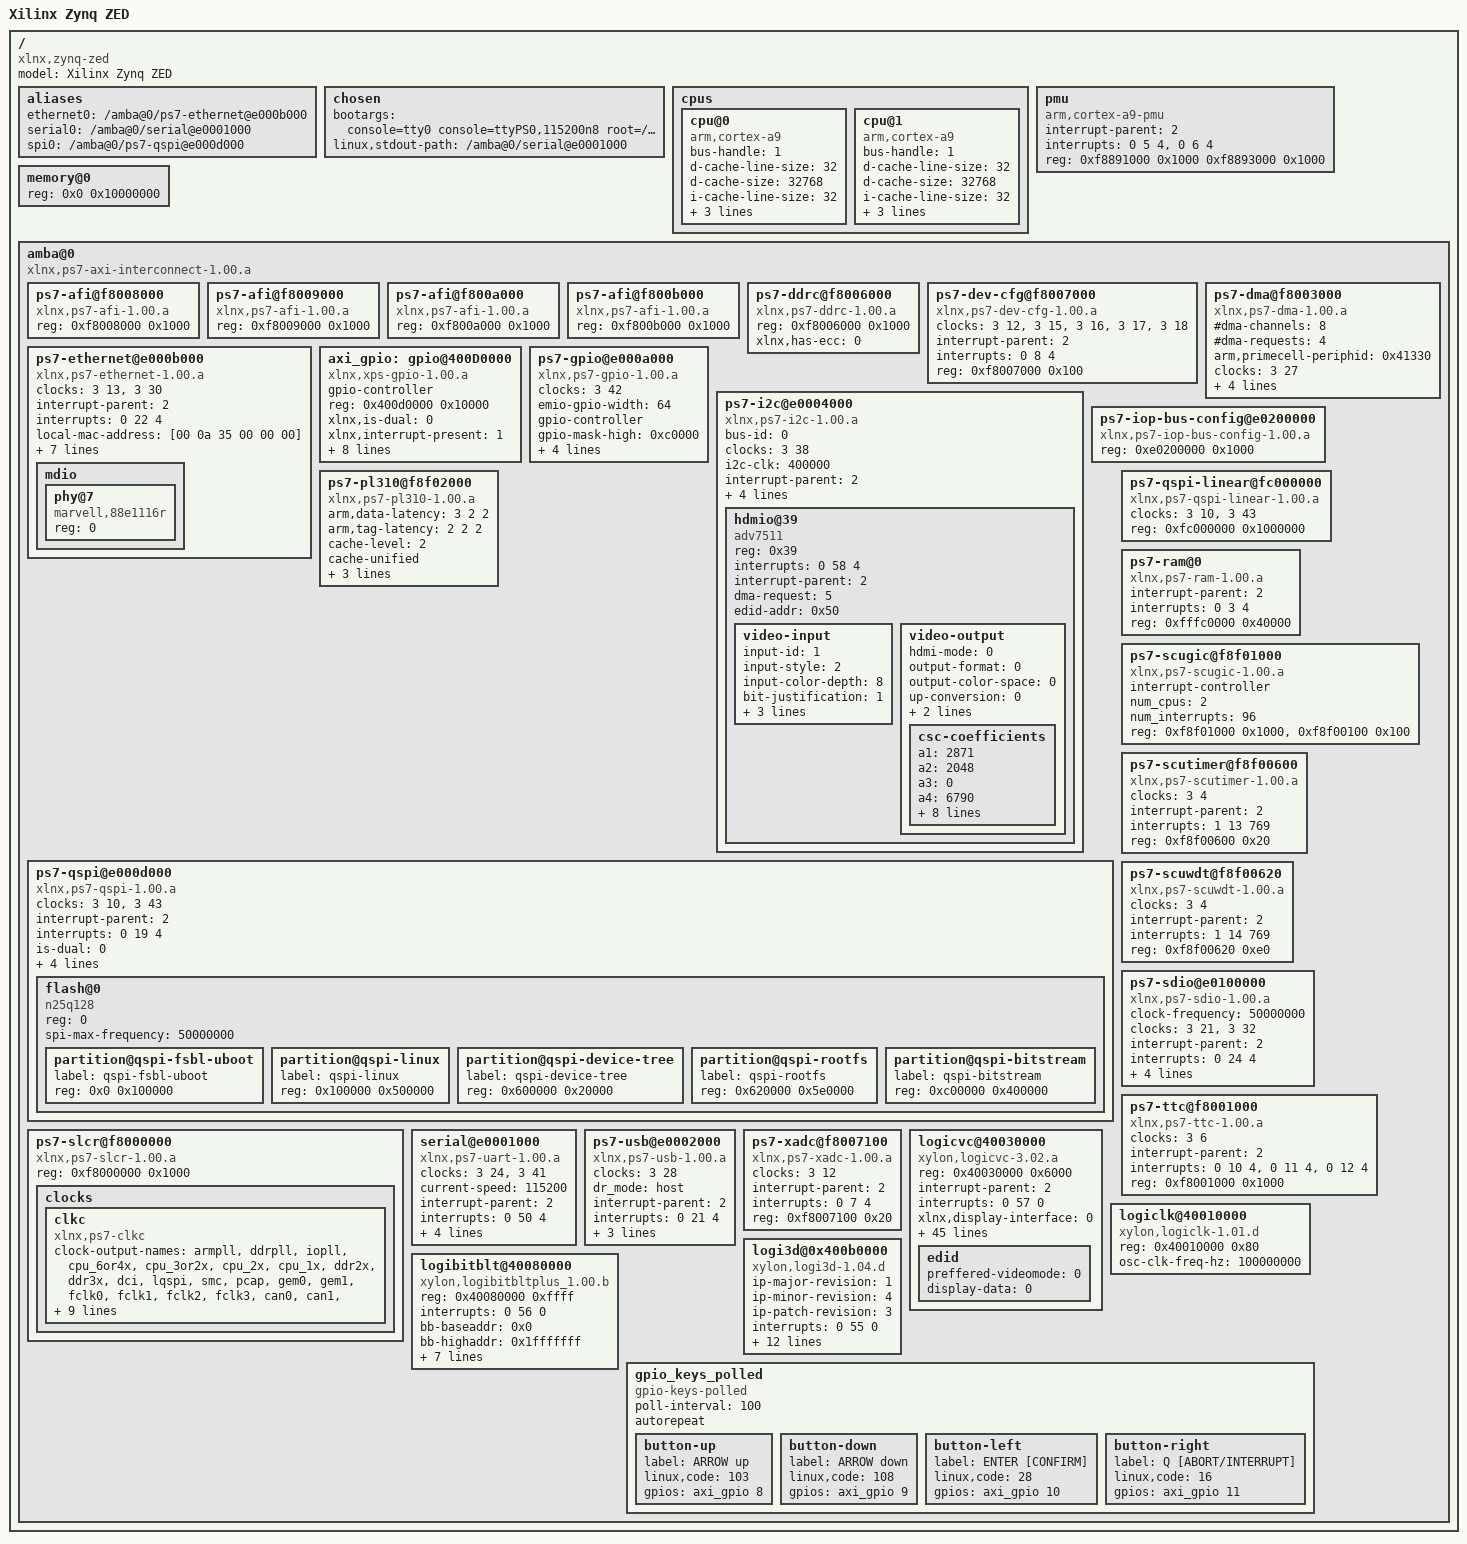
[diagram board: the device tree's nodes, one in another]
/dts-v1/;

/ {
	#address-cells = <1>;
	#size-cells = <1>;
	model = "Xilinx Zynq ZED";
	compatible = "xlnx,zynq-zed", "xlnx,zynq-7000";

	aliases {
		ethernet0 = "/amba@0/ps7-ethernet@e000b000";
		serial0 = "/amba@0/serial@e0001000";
		spi0 = "/amba@0/ps7-qspi@e000d000";
	};

	chosen {
		bootargs = "console=tty0 console=ttyPS0,115200n8 root=/dev/ram rw ip=192.168.0.79:::255.255.255.0:ZED:eth0 earlyprintk";
		linux,stdout-path = "/amba@0/serial@e0001000";
	};

	cpus {
		#address-cells = <1>;
		#size-cells = <0>;

		cpu@0 {
			bus-handle = <1>;
			compatible = "arm,cortex-a9";
			d-cache-line-size = <32>;
			d-cache-size = <32768>;
			device_type = "cpu";
			i-cache-line-size = <32>;
			i-cache-size = <32768>;
			interrupt-handle = <2>;
			reg = <0>;
		};

		cpu@1 {
			bus-handle = <1>;
			compatible = "arm,cortex-a9";
			d-cache-line-size = <32>;
			d-cache-size = <32768>;
			device_type = "cpu";
			i-cache-line-size = <32>;
			i-cache-size = <32768>;
			interrupt-handle = <2>;
			reg = <1>;
		};
	};

	pmu {
		compatible = "arm,cortex-a9-pmu";
		interrupt-parent = <2>;
		interrupts = <0 5 4>, <0 6 4>;
		reg = <0xf8891000 0x1000 0xf8893000 0x1000>;
		reg-names = "cpu0", "cpu1";
	};

	memory@0 {
		device_type = "memory";
		reg = <0x0 0x10000000>;
	};

	amba@0 {
		#address-cells = <1>;
		#size-cells = <1>;
		compatible = "xlnx,ps7-axi-interconnect-1.00.a", "simple-bus";
		ranges;
		linux,phandle = <1>;
		phandle = <1>;

		ps7-afi@f8008000 {
			compatible = "xlnx,ps7-afi-1.00.a";
			reg = <0xf8008000 0x1000>;
		};

		ps7-afi@f8009000 {
			compatible = "xlnx,ps7-afi-1.00.a";
			reg = <0xf8009000 0x1000>;
		};

		ps7-afi@f800a000 {
			compatible = "xlnx,ps7-afi-1.00.a";
			reg = <0xf800a000 0x1000>;
		};

		ps7-afi@f800b000 {
			compatible = "xlnx,ps7-afi-1.00.a";
			reg = <0xf800b000 0x1000>;
		};

		ps7-ddrc@f8006000 {
			compatible = "xlnx,ps7-ddrc-1.00.a", "xlnx,ps7-ddrc";
			reg = <0xf8006000 0x1000>;
			xlnx,has-ecc = <0>;
		};

		ps7-dev-cfg@f8007000 {
			clock-names = "ref_clk", "fclk0", "fclk1", "fclk2", "fclk3";
			clocks = <3 12>, <3 15>, <3 16>, <3 17>, <3 18>;
			compatible = "xlnx,ps7-dev-cfg-1.00.a";
			interrupt-parent = <2>;
			interrupts = <0 8 4>;
			reg = <0xf8007000 0x100>;
		};

		ps7-dma@f8003000 {
			#dma-cells = <1>;
			#dma-channels = <8>;
			#dma-requests = <4>;
			arm,primecell-periphid = <0x41330>;
			clock-names = "apb_pclk";
			clocks = <3 27>;
			compatible = "xlnx,ps7-dma-1.00.a", "arm,primecell", "arm,pl330";
			interrupt-names = "abort", "dma0", "dma1", "dma2", "dma3", "dma4", "dma5", "dma6", "dma7";
			interrupt-parent = <2>;
			interrupts = <0 13 4>, <0 14 4>, <0 15 4>, <0 16 4>, <0 17 4>, <0 40 4>, <0 41 4>, <0 42 4>, <0 43 4>;
			reg = <0xf8003000 0x1000>;
		};

		ps7-ethernet@e000b000 {
			#address-cells = <1>;
			#size-cells = <0>;
			clock-names = "ref_clk", "aper_clk";
			clocks = <3 13>, <3 30>;
			compatible = "xlnx,ps7-ethernet-1.00.a";
			interrupt-parent = <2>;
			interrupts = <0 22 4>;
			local-mac-address = [00 0a 35 00 00 00];
			phy-handle = <4>;
			phy-mode = "rgmii-id";
			reg = <0xe000b000 0x1000>;
			xlnx,enet-reset = <0xffffffff>;
			xlnx,eth-mode = <1>;
			xlnx,has-mdio = <1>;
			xlnx,ptp-enet-clock = <111111115>;

			mdio {
				#address-cells = <1>;
				#size-cells = <0>;

				phy@7 {
					compatible = "marvell,88e1116r";
					device_type = "ethernet-phy";
					reg = <0>;
					linux,phandle = <4>;
					phandle = <4>;
				};
			};
		};

		axi_gpio: gpio@400D0000 {
			#gpio-cells = <2>;
			compatible = "xlnx,xps-gpio-1.00.a";
			gpio-controller;
			reg = <0x400d0000 0x10000>;
			//interrupt-parent = <2>;
			//interrupts = <59 0>;
			xlnx,is-dual = <0>;
			xlnx,interrupt-present = <1>;

			xlnx,all-inputs = <0x1fff>;
			xlnx,dout-default = <0x0000>;
			xlnx,gpio-width = <13>;
			xlnx,tri-default = <0x0000>;

			xlnx,all-inputs-2 = <0x0000>;
			xlnx,dout-default-2 = <0x0000>;
			xlnx,gpio2-width = <32>;
			xlnx,tri-default-2 = <0xffffffff>;
		};
	

		ps7-gpio@e000a000 {
			#gpio-cells = <2>;
			clocks = <3 42>;
			compatible = "xlnx,ps7-gpio-1.00.a";
			emio-gpio-width = <64>;
			gpio-controller;
			gpio-mask-high = <0xc0000>;
			gpio-mask-low = <0xfe81>;
			interrupt-parent = <2>;
			interrupts = <0 20 4>;
			reg = <0xe000a000 0x1000>;
		};

		ps7-i2c@e0004000 {
			bus-id = <0>;
			clocks = <3 38>;
			compatible = "xlnx,ps7-i2c-1.00.a";
			i2c-clk = <400000>;
			interrupt-parent = <2>;
			interrupts = <0 25 4>;
			reg = <0xe0004000 0x1000>;
			xlnx,has-interrupt = <0>;
			xlnx,i2c-reset = "MIO 46";
			#address-cells = <1>;
			#size-cells = <0>;

			hdmio@39 {
				compatible = "adv7511";
				reg = <0x39>;
				interrupts = <0 58 4>;
				interrupt-parent = <2>;
				dma-request = <5>;
				edid-addr = <0x50>;

				video-input {
					input-id = <1>;
					input-style = <2>;
					input-color-depth = <8>;
					bit-justification = <1>;
					hsync-polarity = <0>;
					vsync-polarity = <0>;
					clock-delay = <3>;
				};

				video-output {
					hdmi-mode = <0>;
					output-format = <0>;
					output-color-space = <0>;
					up-conversion = <0>;
					csc-enable = <1>;
					csc-scaling-factor = <2>;

					csc-coefficients {
						a1 = <2871>;
						a2 = <2048>;
						a3 = <0>;
						a4 = <6790>;
						b1 = <6729>;
						b2 = <2048>;
						b3 = <7487>;
						b4 = <1058>;
						c1 = <0>;
						c2 = <2048>;
						c3 = <3629>;
						c4 = <6420>;
					};
				};
			};
		};

		ps7-iop-bus-config@e0200000 {
			compatible = "xlnx,ps7-iop-bus-config-1.00.a";
			reg = <0xe0200000 0x1000>;
		};

		ps7-pl310@f8f02000 {
			arm,data-latency = <3 2 2>;
			arm,tag-latency = <2 2 2>;
			cache-level = <2>;
			cache-unified;
			compatible = "xlnx,ps7-pl310-1.00.a", "arm,pl310-cache";
			interrupt-parent = <2>;
			interrupts = <0 2 4>;
			reg = <0xf8f02000 0x1000>;
		};

		ps7-qspi@e000d000 {
			clock-names = "ref_clk", "aper_clk";
			clocks = <3 10>, <3 43>;
			compatible = "xlnx,ps7-qspi-1.00.a";
			interrupt-parent = <2>;
			interrupts = <0 19 4>;
			is-dual = <0>;
			num-chip-select = <1>;
			reg = <0xe000d000 0x1000>;
			xlnx,fb-clk = <1>;
			xlnx,qspi-mode = <0>;
			#address-cells = <1>;
			#size-cells = <0>;

			flash@0 {
				compatible = "n25q128";
				reg = <0>;
				spi-max-frequency = <50000000>;
				#address-cells = <1>;
				#size-cells = <1>;

				partition@qspi-fsbl-uboot {
					label = "qspi-fsbl-uboot";
					reg = <0x0 0x100000>;
				};

				partition@qspi-linux {
					label = "qspi-linux";
					reg = <0x100000 0x500000>;
				};

				partition@qspi-device-tree {
					label = "qspi-device-tree";
					reg = <0x600000 0x20000>;
				};

				partition@qspi-rootfs {
					label = "qspi-rootfs";
					reg = <0x620000 0x5e0000>;
				};

				partition@qspi-bitstream {
					label = "qspi-bitstream";
					reg = <0xc00000 0x400000>;
				};
			};
		};

		ps7-qspi-linear@fc000000 {
			clock-names = "ref_clk", "aper_clk";
			clocks = <3 10>, <3 43>;
			compatible = "xlnx,ps7-qspi-linear-1.00.a";
			reg = <0xfc000000 0x1000000>;
		};

		ps7-ram@0 {
			compatible = "xlnx,ps7-ram-1.00.a", "xlnx,ps7-ocm";
			interrupt-parent = <2>;
			interrupts = <0 3 4>;
			reg = <0xfffc0000 0x40000>;
		};

		ps7-scugic@f8f01000 {
			#address-cells = <2>;
			#interrupt-cells = <3>;
			#size-cells = <1>;
			compatible = "xlnx,ps7-scugic-1.00.a", "arm,cortex-a9-gic", "arm,gic";
			interrupt-controller;
			num_cpus = <2>;
			num_interrupts = <96>;
			reg = <0xf8f01000 0x1000>, <0xf8f00100 0x100>;
			linux,phandle = <2>;
			phandle = <2>;
		};

		ps7-scutimer@f8f00600 {
			clocks = <3 4>;
			compatible = "xlnx,ps7-scutimer-1.00.a", "arm,cortex-a9-twd-timer";
			interrupt-parent = <2>;
			interrupts = <1 13 769>;
			reg = <0xf8f00600 0x20>;
		};

		ps7-scuwdt@f8f00620 {
			clocks = <3 4>;
			compatible = "xlnx,ps7-scuwdt-1.00.a";
			device_type = "watchdog";
			interrupt-parent = <2>;
			interrupts = <1 14 769>;
			reg = <0xf8f00620 0xe0>;
		};

		ps7-sdio@e0100000 {
			clock-frequency = <50000000>;
			clock-names = "clk_xin", "clk_ahb";
			clocks = <3 21>, <3 32>;
			compatible = "xlnx,ps7-sdio-1.00.a", "generic-sdhci", "arasan,sdhci";
			interrupt-parent = <2>;
			interrupts = <0 24 4>;
			reg = <0xe0100000 0x1000>;
			xlnx,has-cd = <1>;
			xlnx,has-power = <0>;
			xlnx,has-wp = <1>;
		};

		ps7-slcr@f8000000 {
			compatible = "xlnx,ps7-slcr-1.00.a", "xlnx,zynq-slcr";
			reg = <0xf8000000 0x1000>;

			clocks {
				#address-cells = <1>;
				#size-cells = <0>;

				clkc {
					#clock-cells = <1>;
					clock-output-names = "armpll",
					"ddrpll", "iopll", "cpu_6or4x",
					"cpu_3or2x", "cpu_2x", "cpu_1x",
					"ddr2x", "ddr3x", "dci", "lqspi",
					"smc", "pcap", "gem0", "gem1", "fclk0",
					"fclk1", "fclk2", "fclk3", "can0",
					"can1", "sdio0", "sdio1", "uart0",
					"uart1", "spi0", "spi1", "dma",
					"usb0_aper", "usb1_aper", "gem0_aper",
					"gem1_aper", "sdio0_aper",
					"sdio1_aper", "spi0_aper", "spi1_aper",
					"can0_aper", "can1_aper", "i2c0_aper",
					"i2c1_aper", "uart0_aper",
					"uart1_aper", "gpio_aper",
					"lqspi_aper", "smc_aper", "swdt",
					"dbg_trc", "dbg_apb";
					compatible = "xlnx,ps7-clkc";
					fclk-enable = <0xf>;
					ps-clk-frequency = <33333333>;
					linux,phandle = <3>;
					phandle = <3>;
				};
			};
		};

		ps7-ttc@f8001000 {
			clocks = <3 6>;
			compatible = "xlnx,ps7-ttc-1.00.a", "cdns,ttc";
			interrupt-names = "ttc0", "ttc1", "ttc2";
			interrupt-parent = <2>;
			interrupts = <0 10 4>, <0 11 4>, <0 12 4>;
			reg = <0xf8001000 0x1000>;
		};

		serial@e0001000 {
			clock-names = "ref_clk", "aper_clk";
			clocks = <3 24>, <3 41>;
			compatible = "xlnx,ps7-uart-1.00.a", "xlnx,xuartps";
			current-speed = <115200>;
			device_type = "serial";
			interrupt-parent = <2>;
			interrupts = <0 50 4>;
			port-number = <0>;
			reg = <0xe0001000 0x1000>;
			xlnx,has-modem = <0>;
			xlnx,uart-clk-freq-hz = <50000000>;
		};

		ps7-usb@e0002000 {
			clocks = <3 28>;
			compatible = "xlnx,ps7-usb-1.00.a";
			dr_mode = "host";
			interrupt-parent = <2>;
			interrupts = <0 21 4>;
			phy_type = "ulpi";
			reg = <0xe0002000 0x1000>;
			xlnx,usb-reset = <0xffffffff>;
		};

		ps7-xadc@f8007100 {
			clocks = <3 12>;
			compatible = "xlnx,ps7-xadc-1.00.a";
			interrupt-parent = <2>;
			interrupts = <0 7 4>;
			reg = <0xf8007100 0x20>;
		};

		logicvc@40030000 {
			compatible = "xylon,logicvc-3.02.a";
			reg = <0x40030000 0x6000>;
			interrupt-parent = <2>;
			interrupts = <0 57 0>;
			xlnx,display-interface = <0>;
			xlnx,display-color-space = <1>;
			xlnx,ip-license-type = <0>;
			xlnx,ip-major-revision = <3>;
			xlnx,ip-minor-revision = <0>;
			xlnx,ip-patch-level = <0>;
			xlnx,num-of-layers = <5>;
			xlnx,layer-0-type = <0>;
			xlnx,layer-0-alpha-mode = <1>;
			xlnx,layer-0-data-width = <24>;
			xlnx,layer-0-offset = <7290>;
			xlnx,layer-1-type = <0>;
			xlnx,layer-1-alpha-mode = <0>;
			xlnx,layer-1-data-width = <24>;
			xlnx,layer-1-offset = <4050>;
			xlnx,layer-2-type = <0>;
			xlnx,layer-2-alpha-mode = <0>;
			xlnx,layer-2-data-width = <24>;
			xlnx,layer-2-offset = <0>;
			xlnx,layer-3-type = <0>;
			xlnx,layer-3-alpha-mode = <3>;
			xlnx,layer-3-data-width = <8>;
			xlnx,layer-3-offset = <12960>;
			xlnx,layer-4-type = <0>;
			xlnx,layer-4-alpha-mode = <0>;
			xlnx,layer-4-data-width = <24>;
			xlnx,layer-4-offset = <8192>;
			xlnx,buffer-0-offset = <1080>;
			xlnx,buffer-1-offset = <1080>;
			xlnx,buffer-2-offset = <1080>;
			xlnx,buffer-3-offset = <1080>;
			xlnx,buffer-4-offset = <1080>;
			xlnx,little-endian = <1>;
			xlnx,readable-regs = <0>;
			xlnx,row-stride = <2048>;
			xlnx,use-background = <1>;
			xlnx,use-size-position = <1>;
			xlnx,vmem-baseaddr = <0x10000000>;
			xlnx,vmem-highaddr = <0x1fffffff>;
			pixel-clock-source = <2>;
			pixel-data-invert = <0>;
			pixel-clock-active-high = <0>;
			pixel-component-format = "ARGB";
			pixel-component-layer = <0 1 2>;
			active-layer = <3>;
			videomode = "1024x768";
			linux,phandle = <5>;
			phandle = <5>;

			edid {
				preffered-videomode = <0>;
				display-data = <0>;
			};
		};

		logiclk@40010000 {
			compatible = "xylon,logiclk-1.01.d";
			reg = <0x40010000 0x80>;
			osc-clk-freq-hz = <100000000>;
		};

		logibitblt@40080000 {
			compatible = "xylon,logibitbltplus_1.00.b";
			reg = <0x40080000 0xffff>;
			interrupts = <0 56 0>;
			bb-baseaddr = <0x0>;
			bb-highaddr = <0x1fffffff>;
			use-expand = <1>;
			use-patt-fill = <1>;
			use-porter-duff = <1>;
			use-aa-font-expand = <1>;
			use-global-alpha = <1>;
			use-scale = <1>;
			use-scale-bilinear = <1>;
		};

		logi3d@0x400b0000 {
			compatible = "xylon,logi3d-1.04.d";
			ip-major-revision = <1>;
			ip-minor-revision = <4>;
			ip-patch-revision = <3>;
			interrupts = <0 55 0>;
			reg = <0x400b0000 0x400>;
			buffer-offset = <1080>;
			xy-length = <11>;
			uv-length = <11>;
			use-multitexture = <0>;
			use-stencil = <1>;
			use-aa = <1>;
			pixel-componenet-format = "ARGB";
			sw-mem-3d-internal = <0x16000000 0xa000000>;
			sw-video-mem = <0x0 0x20000000>;
			default-fb-name = "/dev/fb2";
			default-cvc-layer = <0 1>;
		};

		gpio_keys_polled {
			compatible = "gpio-keys-polled";
			#address-cells = <1>;
			#size-cells = <0>;
			poll-interval = <100>;
			autorepeat;

			button-up {
				label = "ARROW up";
				linux,code = <103>;
				gpios = <&axi_gpio 8 0>;
			};

			button-down {
				label = "ARROW down";
				linux,code = <108>;
				gpios = <&axi_gpio 9 0>;
			};

			button-left {
				label = "ENTER [CONFIRM]";
				linux,code = <28>;
				gpios = <&axi_gpio 10 0>;
			};

			button-right {
				label = "Q [ABORT/INTERRUPT]";
				linux,code = <16>;
				gpios = <&axi_gpio 11 0>;
			};


			//button-left {
			//	label = "ARROW left";
			//	linux,code = <105>;
			//	gpios = <&axi_gpio 10 0>;
			//};

			//button-right {
			//	label = "ARROW right";
			//	linux,code = <106>;
			//	gpios = <&axi_gpio 11 0>;
			//};

			//button-center {
			//	label = "ENTER";
			//	linux,code = <28>;
			//	gpios = <&axi_gpio 12 0>;
			//};
		};
	};
};
